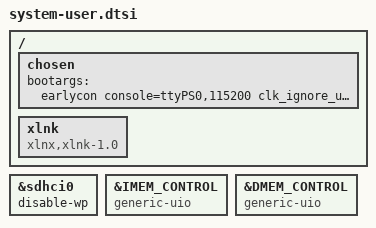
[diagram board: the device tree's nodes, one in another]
/include/ "system-conf.dtsi"
/ {
    chosen {
        bootargs = "earlycon console=ttyPS0,115200 clk_ignore_unused root=/dev/mmcblk0p2 rw rootwait cma=512M uio_pdrv_genirq.of_id=generic-uio";
    };
    xlnk {
        compatible = "xlnx,xlnk-1.0";
    };

};

&sdhci0 {
    disable-wp;
};

&IMEM_CONTROL {
    compatible = "generic-uio";
};

&DMEM_CONTROL {
    compatible = "generic-uio";
};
